# FM33LE0XXA register map
File version: 1.0
CPU: SC000 r1p0, little endian, no MPU, no FPU, 3 interrupt priority bits
Registers are 32-bit, read-write, reset 0x0 unless marked. A register's access mark holds for its fields unless they carry their own. Offsets are from the block's base; [hi:lo] are bit positions.

## I2C — I2C module information
Base 0x40012400
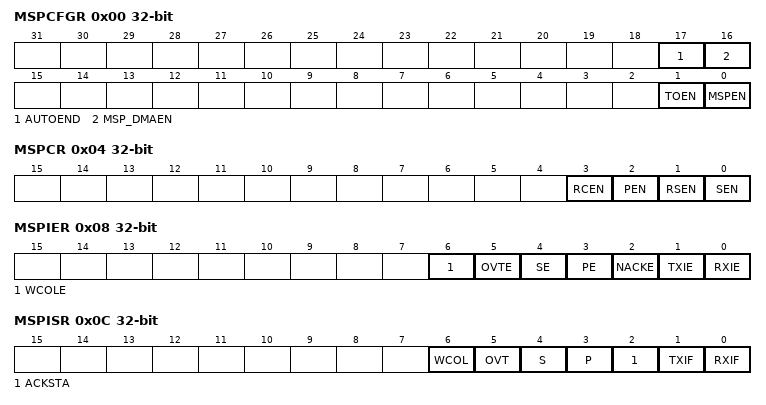
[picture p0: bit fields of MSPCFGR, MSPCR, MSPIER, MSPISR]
0x00 MSPCFGR — I2C Master Config Register
  [17] AUTOEND — AUTOEND field description
  [16] MSP_DMAEN — MSP_DMAEN field description
  [1] TOEN — TOEN field description
  [0] MSPEN — MSPEN field description
0x04 MSPCR — I2C Master Control Register
  [3] RCEN — RCEN field description
  [2] PEN — PEN field description
  [1] RSEN — RSEN field description
  [0] SEN — SEN field description
0x08 MSPIER — I2C Master Intterupt Enable Register
  [6] WCOLE — WCOLE field description
  [5] OVTE — OVTE field description
  [4] SE — SE field description
  [3] PE — PE field description
  [2] NACKE — NACKE field description
  [1] TXIE — TXIE field description
  [0] RXIE — RXIE field description
0x0C MSPISR access per field — I2C Master Interrupt Status Register
  [6] WCOL rw — WCOL field description
  [5] OVT ro — OVT field description
  [4] S ro — S field description
  [3] P ro — P field description
  [2] ACKSTA rw — ACKSTA field description
  [1] TXIF rw — TXIF field description
  [0] RXIF rw — RXIF field description
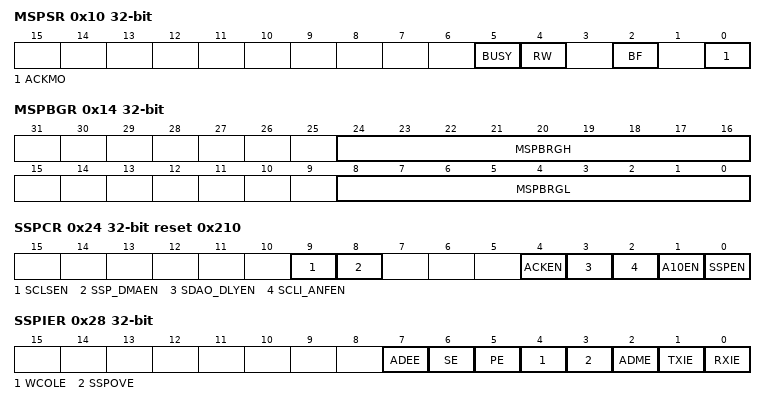
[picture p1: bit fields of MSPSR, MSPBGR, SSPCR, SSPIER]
0x10 MSPSR access per field — I2C Master Status Register
  [5] BUSY ro — BUSY field description
  [4] RW ro — RW field description
  [2] BF ro — BF field description
  [0] ACKMO rw — ACKMO field description
0x14 MSPBGR — I2C Master Baud rate Generator Register
  [24:16] MSPBRGH — MSPBRGH field description
  [8:0] MSPBRGL — MSPBRGL field description
0x18 MSPBUF — I2C Master transfer Buffer
  [7:0] MSPBUF — MSPBUF field description
0x1C MSPTCR — I2C Master Timing Control Register
  [8:0] SDAHD — SDAHD field description
0x20 MSPTOR reset 0xF00 — I2C Master Time-Out Register
  [11:0] TIMEOUT — TIMEOUT field description
0x24 SSPCR reset 0x210 — I2C Slave Control Register
  [9] SCLSEN — SCLSEN field description
  [8] SSP_DMAEN — SSP_DMAEN field description
  [4] ACKEN — ACKEN field description
  [3] SDAO_DLYEN — SDAO_DLYEN field description
  [2] SCLI_ANFEN — SCLI_ANFEN field description
  [1] A10EN — A10EN field description
  [0] SSPEN — SSPEN field description
0x28 SSPIER — I2C Slave Interrupt Enable Register
  [7] ADEE — ADEE field description
  [6] SE — SE field description
  [5] PE — PE field description
  [4] WCOLE — WCOLE field description
  [3] SSPOVE — SSPOVE field description
  [2] ADME — ADME field description
  [1] TXIE — TXIE field description
  [0] RXIE — RXIE field description
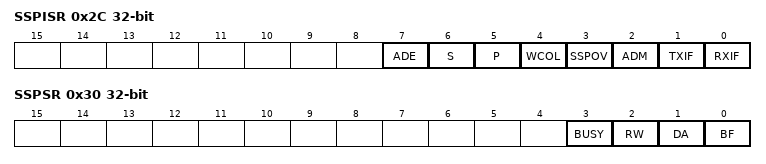
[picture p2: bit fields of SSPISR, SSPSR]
0x2C SSPISR access per field — I2C Slave Interrupt Status Register
  [7] ADE rw — ADE field description
  [6] S ro — S field description
  [5] P ro — P field description
  [4] WCOL rw — WCOL field description
  [3] SSPOV rw — SSPOV field description
  [2] ADM rw — ADM field description
  [1] TXIF rw — TXIF field description
  [0] RXIF rw — RXIF field description
0x30 SSPSR ro — I2C Slave Status Register
  [3] BUSY — BUSY field description
  [2] RW — RW field description
  [1] DA — DA field description
  [0] BF — BF field description
0x34 SSPBUF — I2C Slave transfer Buffer
  [7:0] SSPBUF — SSPBUF field description
0x38 SSPADR — I2C Slave Address Register
  [9:0] SSPADDR — SSPADDR field description

## UARTIR — UARTIR module information
Base 0x40019C00
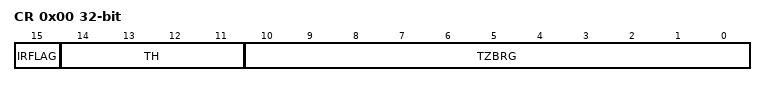
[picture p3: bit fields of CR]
0x00 CR — Infrared modulation Control Register
  [15] IRFLAG — IRFLAG field description
  [14:11] TH — TH field description
  [10:0] TZBRG — TZBRG field description

## UART0 — UART0 module information
Base 0x40011C00
Same registers: UART1 0x40012000
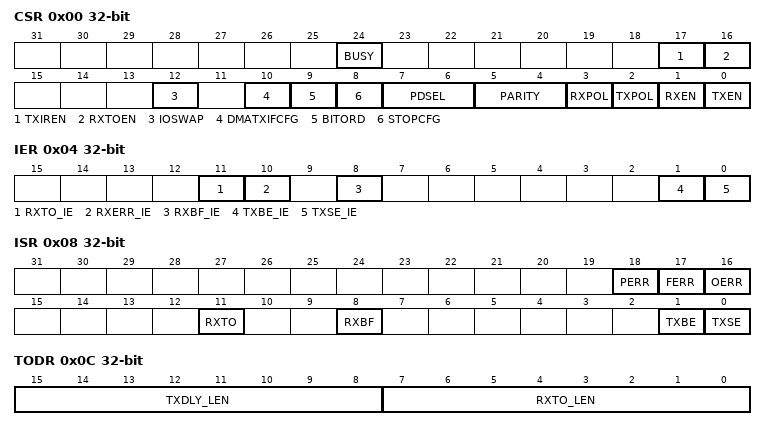
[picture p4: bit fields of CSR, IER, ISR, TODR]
0x00 CSR access per field — UART0 Control Status Register
  [24] BUSY ro — BUSY field description
  [17] TXIREN rw — TXIREN field description
  [16] RXTOEN rw — RXTOEN field description
  [12] IOSWAP rw — IOSWAP field description
  [10] DMATXIFCFG rw — DMATXIFCFG field description
  [9] BITORD rw — BITORD field description
  [8] STOPCFG rw — STOPCFG field description
  [7:6] PDSEL rw — PDSEL field description
  [5:4] PARITY rw — PARITY field description
  [3] RXPOL rw — RXPOL field description
  [2] TXPOL rw — TXPOL field description
  [1] RXEN rw — RXEN field description
  [0] TXEN rw — TXEN field description
0x04 IER — UART0 Interrupt Enable Register
  [11] RXTO_IE — RXTO_IE field description
  [10] RXERR_IE — RXERR_IE field description
  [8] RXBF_IE — RXBF_IE field description
  [1] TXBE_IE — TXBE_IE field description
  [0] TXSE_IE — TXSE_IE field description
0x08 ISR access per field — UART0 Interrupt Status Register
  [18] PERR rw — PERR field description
  [17] FERR rw — FERR field description
  [16] OERR rw — OERR field description
  [11] RXTO rw — RXTO field description
  [8] RXBF rw — RXBF field description
  [1] TXBE ro — TXBE field description
  [0] TXSE rw — TXSE field description
0x0C TODR — UART0 Time-Out and Delay Register
  [15:8] TXDLY_LEN — TXDLY_LEN field description
  [7:0] RXTO_LEN — RXTO_LEN field description
0x10 RXBUF ro — UART0 Receive Buffer
  [8:0] RXBUF — RXBUF field description
0x14 TXBUF — UART0 Transmit Buffer
  [8:0] TXBUF — TXBUF field description
0x18 BGR — UART0 Baud rate Generator Register
  [15:0] SPBRG — SPBRG field description

## UART4 — UART4 module information
Base 0x4001A000
Same registers: UART5 0x4001A400
Registers as UART0 (with UART0 read as UART4), without TODR.
